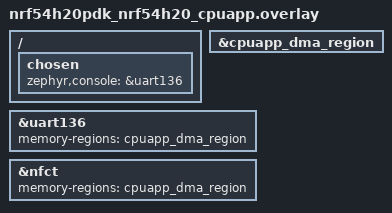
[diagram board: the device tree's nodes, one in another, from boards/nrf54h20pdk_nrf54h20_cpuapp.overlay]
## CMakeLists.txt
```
#
# Copyright (c) 2023 Nordic Semiconductor
#
# SPDX-License-Identifier: LicenseRef-Nordic-5-Clause
#

cmake_minimum_required(VERSION 3.20.0)

find_package(Zephyr REQUIRED HINTS $ENV{ZEPHYR_BASE})
project(NONE)

# NORDIC SDK APP START
target_sources(app  PRIVATE src/main.c)
# NORDIC SDK APP END
```

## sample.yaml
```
sample:
  description: NFC Shell sample
  name: NFC Shell
tests:
  sample.nfc.shell:
    sysbuild: true
    build_only: true
    integration_platforms:
      - nrf52840dk/nrf52840
      - nrf5340dk/nrf5340/cpuapp
      - nrf5340dk/nrf5340/cpuapp/ns
      - nrf54h20dk/nrf54h20/cpuapp
      - nrf54l15dk/nrf54l05/cpuapp
      - nrf54l15dk/nrf54l10/cpuapp
      - nrf54l15dk/nrf54l15/cpuapp
      - nrf54lm20dk/nrf54lm20a/cpuapp
      - nrf7120dk/nrf7120/cpuapp
    platform_allow:
      - nrf52840dk/nrf52840
      - nrf52dk/nrf52832
      - nrf5340dk/nrf5340/cpuapp
      - nrf5340dk/nrf5340/cpuapp/ns
      - nrf54h20dk/nrf54h20/cpuapp
      - nrf54l15dk/nrf54l05/cpuapp
      - nrf54l15dk/nrf54l10/cpuapp
      - nrf54l15dk/nrf54l15/cpuapp
      - nrf54lm20dk/nrf54lm20a/cpuapp
      - nrf7120dk/nrf7120/cpuapp
    tags:
      - ci_build
      - sysbuild
      - ci_samples_nfc
  sample.nfc.shell.llvm:
    toolchain_allow: llvm
    sysbuild: true
    build_only: true
    integration_platforms:
      - nrf54l15dk/nrf54l15/cpuapp
    platform_allow:
      - nrf54l15dk/nrf54l15/cpuapp
    tags:
      - ci_build
      - sysbuild
      - ci_samples_nfc
```

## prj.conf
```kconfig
#
# Copyright (c) 2023 Nordic Semiconductor ASA
#
# SPDX-License-Identifier: LicenseRef-Nordic-5-Clause
#

CONFIG_DK_LIBRARY=y

CONFIG_SHELL=y
CONFIG_SHELL_NFC=y

# Disable serial backend and use UART for logger purpose.
CONFIG_SHELL_BACKEND_SERIAL=n

CONFIG_NFC_T4T_NRFXLIB=y

CONFIG_LOG=y
CONFIG_LOG_MODE_DEFERRED=y
CONFIG_LOG_PRINTK=y

CONFIG_ASSERT=y
CONFIG_ASSERT_MODULE_DEFAULT_LEVEL_TERSE=y
```

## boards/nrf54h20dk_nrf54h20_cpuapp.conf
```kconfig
#
# Copyright (c) 2026 Nordic Semiconductor ASA
#
# SPDX-License-Identifier: LicenseRef-Nordic-5-Clause
#

# Enable device power management
CONFIG_PM_DEVICE=y
CONFIG_PM_DEVICE_RUNTIME=y

# Enable system power management
CONFIG_PM=y

# Enable power off state
CONFIG_POWEROFF=y

# Enable cpurad for sysbuild
CONFIG_SOC_NRF54H20_CPURAD_ENABLE=y
```

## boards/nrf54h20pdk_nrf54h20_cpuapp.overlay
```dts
/*
 * Copyright (c) 2023 Nordic Semiconductor ASA
 *
 * SPDX-License-Identifier: LicenseRef-Nordic-5-Clause
 */

/ {
	chosen {
		zephyr,console = &uart136;
	};
};

&cpuapp_dma_region {
	status = "okay";
};

&uart136 {
	status = "okay";
	memory-regions = <&cpuapp_dma_region>;
};

&nfct {
	status = "okay";
	memory-regions = <&cpuapp_dma_region>;
};
```

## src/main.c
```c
/*
 * Copyright (c) 2023 Nordic Semiconductor ASA
 *
 * SPDX-License-Identifier: LicenseRef-Nordic-5-Clause
 */

#include <zephyr/kernel.h>
#include <zephyr/shell/shell.h>

#include <dk_buttons_and_leds.h>

#define RUN_STATUS_LED DK_LED1
#define SHELL_LED      DK_LED2

#define STATUS_LED_INTERVAL K_MSEC(1000)

int main(void)
{
	uint32_t blink_status = 0;
	int err;

	printk("Starting NFC shell sample\n");

	err = dk_leds_init();
	if (err) {
		printk("LEDs init failed (err %d)\n", err);
		return 1;
	}

	for (;;) {
		dk_set_led(RUN_STATUS_LED, (++blink_status) % 2);
		k_sleep(STATUS_LED_INTERVAL);
	}
	return 0;
}

static int led_on_handler(const struct shell *shell, size_t argc, char **argv)
{
	int err = dk_set_led_on(SHELL_LED);

	if (err) {
		shell_error(shell, "Failed to turn on the LED, (err: %d)", err);
		return err;
	}

	shell_print(shell, "The LED is on");

	return 0;
}

static int led_off_handler(const struct shell *shell, size_t argc, char **argv)
{
	int err = dk_set_led_off(SHELL_LED);

	if (err) {
		shell_error(shell, "Failed to turn off the LED, (err: %d)", err);
		return err;
	}

	shell_print(shell, "The LED is off");

	return 0;
}

SHELL_STATIC_SUBCMD_SET_CREATE(
	led_subcmd,
	SHELL_CMD(on, NULL, "Turn on DK LED", led_on_handler),
	SHELL_CMD(off, NULL, "Turn off DK LED", led_off_handler),
	SHELL_SUBCMD_SET_END
);

SHELL_CMD_REGISTER(led, &led_subcmd, "Control DK LED", NULL);
```
